# M0519AE_v1 register map
File version: 1.0
Registers are 32-bit, read-write, reset 0x0 unless marked. A register's access mark holds for its fields unless they carry their own. Offsets are from the block's base; [hi:lo] are bit positions.

## WWDT — WWDT Register Map
Base 0x40004100
0x00 WWDTRLD wo — WWDT Reload Counter Register
  [31:0] WWDTRLD — WWDT Reload Counter Register. Writing 0x00005AA5 to this register will reload the WWDT counter value to 0x3F. Note: User can only write WWDTRLD to reload WWDT counter value when current WWDT counter value between 0 and WINCMP (WWDTCR[21:16]). If user writes WWDTRLD when current WWDT counter value is larger than WINCMP, WWDT reset signal will generate immediately.
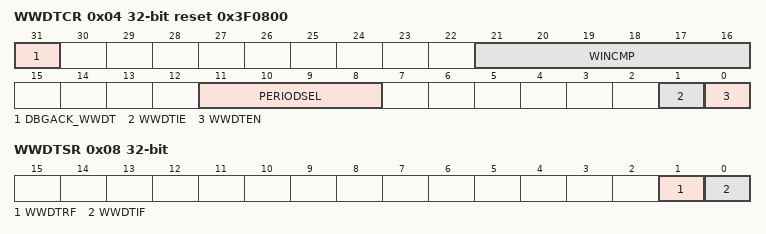
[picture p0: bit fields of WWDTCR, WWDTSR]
0x04 WWDTCR reset 0x3F0800 — WWDT Control Register
  [31] DBGACK_WWDT — ICE Debug Mode Acknowledge Disable Control. WWDT down counter will keep going no matter CPU is held by ICE or not.
    0=ICE debug mode acknowledgement effects WWDT counting; 1=ICE debug mode acknowledgement Disabled
  [21:16] WINCMP — WWDT Window Compare Register. Set this register to adjust the valid reload window. Note: User can only write WWDTRLD to reload WWDT counter value when current WWDT counter value between 0 and WINCMP. If user writes WWDTRLD when current WWDT counter value larger than WINCMP, WWDT reset signal will generate immediately.
  [11:8] PERIODSEL — WWDT Counter Prescale Period Selection
    0=Pre-scale is 1; Max time-out period is 1 * 64 * WWDT_CLK; 1=Pre-scale is 2; Max time-out period is 2 * 64 * WWDT_CLK; 2=Pre-scale is 4; Max time-out period is 4 * 64 * WWDT_CLK; 3=Pre-scale is 8; Max time-out period is 8 * 64 * WWDT_CLK; 4=Pre-scale is 16; Max time-out period is 16 * 64 * WWDT_CLK; 5=Pre-scale is 32; Max time-out period is 32 * 64 * WWDT_CLK; 6=Pre-scale is 64; Max time-out period is 64 * 64 * WWDT_CLK; 7=Pre-scale is 128; Max time-out period is 128 * 64 * WWDT_CLK; 8=Pre-scale is 192; Max time-out period is 192 * 64 * WWDT_CLK; 9=Pre-scale is 256; Max time-out period is 256 * 64 * WWDT_CLK; 10=Pre-scale is 384; Max time-out period is 384 * 64 * WWDT_CLK; 11=Pre-scale is 512; Max time-out period is 512 * 64 * WWDT_CLK; 12=Pre-scale is 768; Max time-out period is 768 * 64 * WWDT_CLK; 13=Pre-scale is 1024; Max time-out period is 1024 * 64 * WWDT_CLK; 14=Pre-scale is 1536; Max time-out period is 1536 * 64 * WWDT_CLK; 15=Pre-scale is 2048; Max time-out period is 2048 * 64 * WWDT_CLK
  [1] WWDTIE — WWDT Interrupt Enable Bit. If this bit is enabled, the WWDT counter compare match interrupt signal is generated and inform to CPU.
    0=WWDT counter compare match interrupt Disabled; 1=WWDT counter compare match interrupt Enabled
  [0] WWDTEN — WWDT Enable Bit. Set this bit to enable WWDT counter counting
    0=WWDT counter is stopped; 1=WWDT counter is starting counting
0x08 WWDTSR — WWDT Status Register
  [1] WWDTRF — WWDT Time-out Reset Flag. This bit indicates the system has been reset by WWDT time-out reset or not. Note: This bit is cleared by writing 1 to it.
    0=WWDT time-out reset did not occur; 1=WWDT time-out reset occurred
  [0] WWDTIF — WWDT Compare Match Interrupt Flag. This bit indicates the interrupt flag status of WWDT while WWDT counter value matches WINCMP (WWDTCR[21:16]). Note: This bit is cleared by writing 1 to it.
    0=No effect; 1=WWDT counter value matches WINCMP value
0x0C WWDTCVR ro reset 0x3F — WWDT Counter Value Register
  [5:0] WWDTCVAL — WWDT Counter Value. WWDTCVAL will be updated continuously to monitor 6-bit down counter value.

## HDIV — HDIV Register Map
Base 0x50014000
0x04 DIVIDEND — Dividend Source Register (Signed 32-bit)
  [31:0] Dividend — Dividend Source. This register is given the dividend (signed 32-bit) of divider before calculation starts.
0x08 DIVISOR reset 0xFFFF — Divisor Source Resister (Signed 16-bit)
  [15:0] Divisor — Divisor Source. This register is given the divisor of divider before calculation starts. Note: When this register is written, hardware divider will start calculation.
0x0C DIVQUO ro — Quotient Result Resister (Signed 32-bit)
  [31:0] Quotient — Quotient Result. This register holds the quotient (signed 32-bit) result of divider after calculation completed.
0x10 DIVREM ro — Reminder Result Register (Signed 16-bit)
  [15:0] Reminder — Reminder Result. This register holds the reminder (signed 16-bit) result of divider after calculation completed.
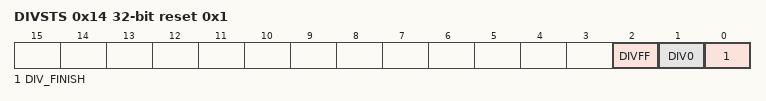
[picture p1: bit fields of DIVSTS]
0x14 DIVSTS reset 0x1 — Divider Status Register
  [2] DIVFF — Divider Operation Finish Flag. When divider calculation has finished, this bit is set to 1. This bit is cleared to 0 by writing 1 to it through software
  [1] DIV0 — Divisor Zero Warning. This register is read only.
    0=The divisor is not 0; 1=The divisor is 0
  [0] DIV_FINISH — Divider Operation Finished. This register is read only.
    0=The divider calculation not finished yet; 1=The divider calculation finished

## OPA — OPA Register Map
Base 0x400F0000
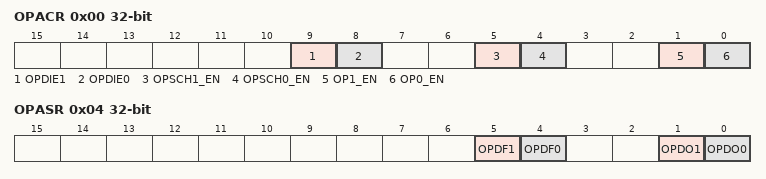
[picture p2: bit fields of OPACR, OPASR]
0x00 OPACR — OP Amplifier Control Register
  [9] OPDIE1 — OP Amplifier 1 Schmitt Trigger Digital Output Interrupt Enable Bit. The OPDF1 interrupt flag is set by hardware whenever the OP amplifier 1 Schmitt trigger non-inverting buffer digital output changes state, in the meanwhile, if OPDIE1 is set to 1, a comparator interrupt request is generated.
    0=OP Amplifier 1 digital output interrupt function Disabled; 1=OP Amplifier 1 digital output interrupt function Enabled
  [8] OPDIE0 — OP Amplifier 0 Schmitt Trigger Digital Output Interrupt Enable Bit. The OPDF0 interrupt flag is set by hardware whenever the OP amplifier 0 Schmitt trigger non-inverting buffer digital output changes state, in the meanwhile, if OPDIE0 is set to 1, a comparator interrupt request is generated.
    0=OP Amplifier 0 digital output interrupt function Disabled; 1=OP Amplifier 0 digital output interrupt function Enabled
  [5] OPSCH1_EN — OP Amplifier 1 Schmitt Trigger Non-inverting Buffer Enable Bit
    0=OP Amplifier 1 Schmitt trigger Disabled; 1=OP Amplifier 1 Schmitt trigger Enabled
  [4] OPSCH0_EN — OP Amplifier 0 Schmitt Trigger Non-inverting Buffer Enable Bit
    0=OP Amplifier 0 Schmitt trigger Disabled; 1=OP Amplifier 0 Schmitt trigger Enabled
  [1] OP1_EN — OP Amplifier 1 Enable Bit
    0=OP Amplifier 1 Disabled; 1=OP Amplifier 1 Enabled
  [0] OP0_EN — OP Amplifier 0 Enable Bit
    0=OP Amplifier 0 Disabled; 1=OP Amplifier 0 Enabled
0x04 OPASR — OP Amplifier Status Register
  [5] OPDF1 — OP Amplifier 1 Schmitt Trigger Digital Output Interrupt Flag. OPDF1 interrupt flag is set by hardware whenever the OP amplifier 1 Schmitt trigger non-inverting buffer digital output changes state. Note: This bit is cleared by writing 1 to it.
  [4] OPDF0 — OP Amplifier 0 Schmitt Trigger Digital Output Interrupt Flag. OPDF0 interrupt flag is set by hardware whenever the OP amplifier 0 Schmitt trigger non-inverting buffer digital output changes state. Note: This bit is cleared by writing 1 to it.
  [1] OPDO1 — OP Amplifier 1 Digital Output
  [0] OPDO0 — OP Amplifier 0 Digital Output
